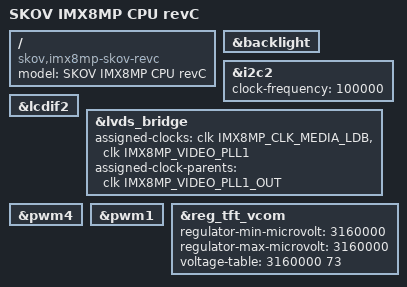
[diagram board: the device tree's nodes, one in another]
// SPDX-License-Identifier: (GPL-2.0 OR MIT)

/dts-v1/;

#include "imx8mp-skov-reva.dtsi"

/ {
	model = "SKOV IMX8MP CPU revC";
	compatible = "skov,imx8mp-skov-revc", "fsl,imx8mp";
};

&backlight {
	status = "okay";
};

&i2c2 {
	clock-frequency = <100000>;
	status = "okay";
};

&lcdif2 {
	status = "okay";
};

&lvds_bridge {
	assigned-clocks = <&clk IMX8MP_CLK_MEDIA_LDB>,
			  <&clk IMX8MP_VIDEO_PLL1>;
	assigned-clock-parents = <&clk IMX8MP_VIDEO_PLL1_OUT>;
	status = "okay";
};

&pwm4 {
	status = "okay";
};

&pwm1 {
	status = "okay";
};

&reg_tft_vcom {
	regulator-min-microvolt = <3160000>;
	regulator-max-microvolt = <3160000>;
	voltage-table = <3160000 73>;
	status = "okay";
};
